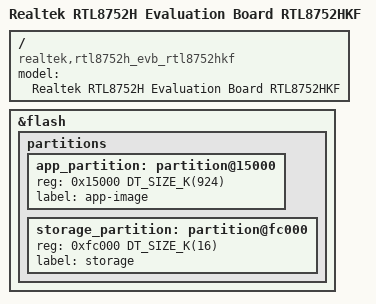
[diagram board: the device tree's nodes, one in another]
/*
 * Copyright (c) 2026, Realtek Semiconductor Corporation.
 *
 * SPDX-License-Identifier: Apache-2.0
 */

/dts-v1/;
#include <realtek/bee/rtl8752hkf.dtsi>
#include "rtl8752h_evb_common.dtsi"

/ {
	compatible = "realtek,rtl8752h_evb_rtl8752hkf";
	model = "Realtek RTL8752H Evaluation Board RTL8752HKF";
};

&flash {
	partitions {
		app_partition: partition@15000 {
			reg = <0x15000 DT_SIZE_K(924)>;
			label = "app-image";
		};

		storage_partition: partition@fc000 {
			reg = <0xfc000 DT_SIZE_K(16)>;
			label = "storage";
		};
	};
};
